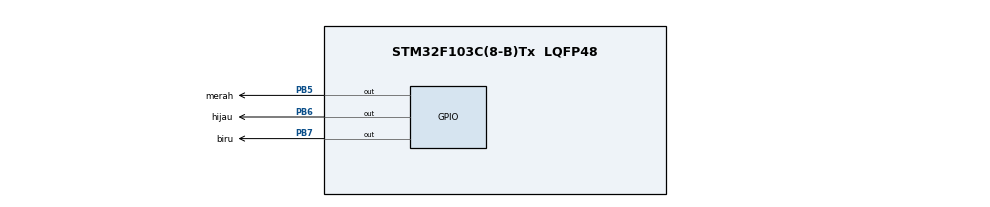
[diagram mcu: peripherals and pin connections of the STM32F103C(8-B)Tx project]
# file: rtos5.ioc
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FREERTOS.Tasks01=defaultTask,0,128,StartDefaultTask,Default,NULL,Dynamic,NULL,NULL;ledmerah,1,128,StartTask02,Default,NULL,Dynamic,NULL,NULL;ledhijau,0,128,StartTask03,Default,NULL,Dynamic,NULL,NULL
Mcu.Family=STM32F1
Mcu.Name=STM32F103C(8-B)Tx
Mcu.Package=LQFP48
NVIC.PriorityGroup=NVIC_PRIORITYGROUP_4
NVIC.TIM2_IRQn=true\:15\:0\:false\:false\:true\:false\:false\:true\:true
NVIC.TimeBase=TIM2_IRQn
NVIC.TimeBaseIP=TIM2
PA13.Mode=Serial_Wire
PA13.Signal=SYS_JTMS-SWDIO
PA14.Mode=Serial_Wire
PA14.Signal=SYS_JTCK-SWCLK
PB5.GPIO_Label=merah
PB5.Signal=GPIO_Output
PB6.GPIO_Label=hijau
PB6.Signal=GPIO_Output
PB7.GPIO_Label=biru
PB7.Signal=GPIO_Output
ProjectManager.HeapSize=0x200
ProjectManager.StackSize=0x400
ProjectManager.TargetToolchain=MDK-ARM V5.32
RCC.APB1Freq_Value=8000000
RCC.APB2Freq_Value=8000000
VP_FREERTOS_VS_CMSIS_V1.Mode=CMSIS_V1
VP_SYS_VS_tim2.Mode=TIM2
board=custom

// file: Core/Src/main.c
/* USER CODE BEGIN Header */
/**
  ******************************************************************************
  * @file           : main.c
  * @brief          : Main program body
  ******************************************************************************
  * @attention
  *
  * Copyright (c) 2024 STMicroelectronics.
  * All rights reserved.
  *
  * This software is licensed under terms that can be found in the LICENSE file
  * in the root directory of this software component.
  * If no LICENSE file comes with this software, it is provided AS-IS.
  *
  ******************************************************************************
  */
/* USER CODE END Header */
#include "main.h"
#include "cmsis_os.h"

osThreadId defaultTaskHandle;
osThreadId ledmerahHandle;
osThreadId ledhijauHandle;

void SystemClock_Config(void);
static void MX_GPIO_Init(void);
void StartDefaultTask(void const * argument);
void StartTask02(void const * argument);
void StartTask03(void const * argument);

/* USER CODE BEGIN 0 */
			uint8_t flagg = 1;
			void accessData(){
				if(flagg == 1) flagg = 0;
				else{
					HAL_GPIO_WritePin(biru_GPIO_Port, biru_Pin, 0);
			//		osDelay(100);
					osDelay(100);
					HAL_GPIO_WritePin(biru_GPIO_Port, biru_Pin, 1);
				}
				osDelay(500);
				flagg = 1;
			}
/* USER CODE END 0 */

int main(void)
{

  /* MCU Configuration--------------------------------------------------------*/

  /* Reset of all peripherals, Initializes the Flash interface and the Systick. */
  HAL_Init();

  /* Configure the system clock */
  SystemClock_Config();

  /* Initialize all configured peripherals */
  MX_GPIO_Init();

  /* Create the thread(s) */
  /* definition and creation of defaultTask */
  osThreadDef(defaultTask, StartDefaultTask, osPriorityNormal, 0, 128);
  defaultTaskHandle = osThreadCreate(osThread(defaultTask), NULL);

  /* definition and creation of ledmerah */
  osThreadDef(ledmerah, StartTask02, osPriorityAboveNormal, 0, 128);
  ledmerahHandle = osThreadCreate(osThread(ledmerah), NULL);

  /* definition and creation of ledhijau */
  osThreadDef(ledhijau, StartTask03, osPriorityNormal, 0, 128);
  ledhijauHandle = osThreadCreate(osThread(ledhijau), NULL);

  /* Start scheduler */
  osKernelStart();

  /* We should never get here as control is now taken by the scheduler */

  /* Infinite loop */
  while (1)
  {

  }
}

void SystemClock_Config(void)
{
  RCC_OscInitTypeDef RCC_OscInitStruct = {0};
  RCC_ClkInitTypeDef RCC_ClkInitStruct = {0};

  /** Initializes the RCC Oscillators according to the specified parameters
  * in the RCC_OscInitTypeDef structure.
  */
  RCC_OscInitStruct.OscillatorType = RCC_OSCILLATORTYPE_HSI;
  RCC_OscInitStruct.HSIState = RCC_HSI_ON;
  RCC_OscInitStruct.HSICalibrationValue = RCC_HSICALIBRATION_DEFAULT;
  RCC_OscInitStruct.PLL.PLLState = RCC_PLL_NONE;
  if (HAL_RCC_OscConfig(&RCC_OscInitStruct) != HAL_OK)
  {
    Error_Handler();
  }

  /** Initializes the CPU, AHB and APB buses clocks
  */
  RCC_ClkInitStruct.ClockType = RCC_CLOCKTYPE_HCLK|RCC_CLOCKTYPE_SYSCLK
                              |RCC_CLOCKTYPE_PCLK1|RCC_CLOCKTYPE_PCLK2;
  RCC_ClkInitStruct.SYSCLKSource = RCC_SYSCLKSOURCE_HSI;
  RCC_ClkInitStruct.AHBCLKDivider = RCC_SYSCLK_DIV1;
  RCC_ClkInitStruct.APB1CLKDivider = RCC_HCLK_DIV1;
  RCC_ClkInitStruct.APB2CLKDivider = RCC_HCLK_DIV1;

  if (HAL_RCC_ClockConfig(&RCC_ClkInitStruct, FLASH_LATENCY_0) != HAL_OK)
  {
    Error_Handler();
  }
}

static void MX_GPIO_Init(void)
{
  GPIO_InitTypeDef GPIO_InitStruct = {0};

  /* GPIO Ports Clock Enable */
  __HAL_RCC_GPIOA_CLK_ENABLE();
  __HAL_RCC_GPIOB_CLK_ENABLE();

  /*Configure GPIO pin Output Level */
  HAL_GPIO_WritePin(GPIOB, merah_Pin|hijau_Pin|biru_Pin, GPIO_PIN_RESET);

  /*Configure GPIO pins : merah_Pin hijau_Pin biru_Pin */
  GPIO_InitStruct.Pin = merah_Pin|hijau_Pin|biru_Pin;
  GPIO_InitStruct.Mode = GPIO_MODE_OUTPUT_PP;
  GPIO_InitStruct.Pull = GPIO_NOPULL;
  GPIO_InitStruct.Speed = GPIO_SPEED_FREQ_LOW;
  HAL_GPIO_Init(GPIOB, &GPIO_InitStruct);

}

void StartDefaultTask(void const * argument)
{
  for(;;)
  {
    osDelay(1);
  }
}

void StartTask02(void const * argument)
{
  /* USER CODE BEGIN StartTask02 */
  /* Infinite loop */
  for(;;)
  {
			  HAL_GPIO_WritePin(merah_GPIO_Port, merah_Pin, 1);
//	  taskENTER_CRITICAL();
				accessData();
//	  taskEXIT_CRITICAL();
				HAL_GPIO_WritePin(merah_GPIO_Port, merah_Pin, 0);
					osDelay(100);

  }
  /* USER CODE END StartTask02 */
}

void StartTask03(void const * argument)
{
  /* USER CODE BEGIN StartTask03 */
  /* Infinite loop */
  for(;;)
  {
					 HAL_GPIO_WritePin(hijau_GPIO_Port, hijau_Pin, 1);
			//	  taskENTER_CRITICAL();
							accessData();
			//	  taskEXIT_CRITICAL();
					HAL_GPIO_WritePin(hijau_GPIO_Port, hijau_Pin, 0);
							osDelay(500);
  }
  /* USER CODE END StartTask03 */
}

void HAL_TIM_PeriodElapsedCallback(TIM_HandleTypeDef *htim)
{
  if (htim->Instance == TIM2) {
    HAL_IncTick();
  }
}

void Error_Handler(void)
{
  __disable_irq();
  while (1)
  {
  }
}
